AUTOSAR XML (schema 4-0-3)
standard types defined: Boolean
package /Svc_FiM
  client server interface FunctionInhibition: is-service=true
    operation GetFunctionPermission: possible-error=E_NOT_OK
      arg Permission: type=Boolean, direction=OUT
    error E_NOT_OK: error-code=1
  impl type FiM_FunctionIdType: category=VALUE, base-type=FiM_BaseType_uint8
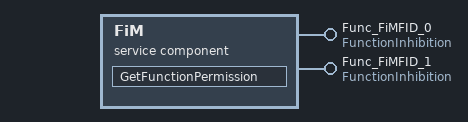
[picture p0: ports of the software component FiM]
  service sw component type FiM
    provide port Func_FiMFID_0: server-com-spec{operation=GetFunctionPermission, queue-length=1}, provided-interface=FunctionInhibition
    provide port Func_FiMFID_1: server-com-spec{operation=GetFunctionPermission, queue-length=1}, provided-interface=FunctionInhibition
    behavior SwcInternalBehavior_0
      operation invoked event OIE_GetFunctionPermission_FiMFID_0: start-on-event=GetFunctionPermission, operation=Func_FiMFID_0.GetFunctionPermission
      operation invoked event OIE_GetFunctionPermission_FiMFID_1: start-on-event=GetFunctionPermission, operation=Func_FiMFID_1.GetFunctionPermission
      port-api-options:
        {enable-take-address=false, indirect-api=false, port-defined-argument-value{value=0, value-type=FiM_FunctionIdType}, port=Func_FiMFID_0}
        {enable-take-address=false, indirect-api=false, port-defined-argument-value{value=1, value-type=FiM_FunctionIdType}, port=Func_FiMFID_1}
      runnable GetFunctionPermission: can-enter-exclusive-area=[REQUEST_EVENTID_PROTECTION, REQUEST_FID_PROTECTION], arguments=[symbol=FID, symbol=Permission], can-be-invoked-concurrently=true, symbol=FiM_GetFunctionPermission
  base type FiM_BaseType_uint8: native-declaration=unsigned char
  impl type FiM_Uint8Type: category=VALUE, base-type=FiM_BaseType_uint8
  base type BooleanBase: base-type-encoding=BaseTypeEncoding, native-declaration=unsigned char
